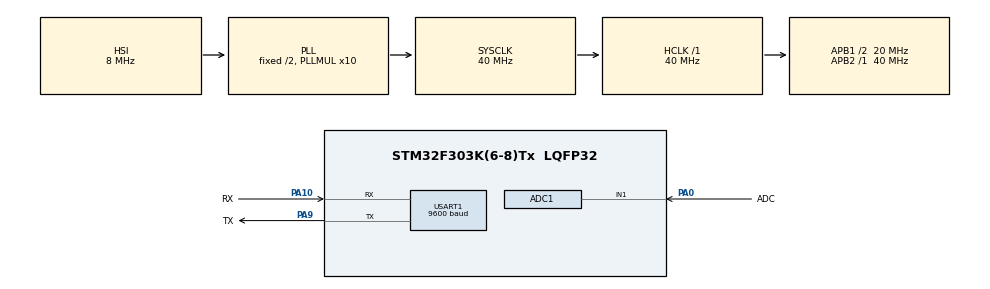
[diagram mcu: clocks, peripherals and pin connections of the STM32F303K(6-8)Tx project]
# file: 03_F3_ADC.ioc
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ADC1.Channel-0\#ChannelRegularConversion=ADC_CHANNEL_1
ADC1.ContinuousConvMode=ENABLE
ADC1.EnableInjectedConversion=DISABLE
ADC1.NbrOfConversionFlag=1
ADC1.Offset-0\#ChannelRegularConversion=0
ADC1.OffsetNumber-0\#ChannelRegularConversion=ADC_OFFSET_NONE
ADC1.Rank-0\#ChannelRegularConversion=1
ADC1.SamplingTime-0\#ChannelRegularConversion=ADC_SAMPLETIME_1CYCLE_5
ADC1.SubFamily=STM32F303x8
ADC1.master=1
Mcu.Family=STM32F3
Mcu.Name=STM32F303K(6-8)Tx
Mcu.Package=LQFP32
NVIC.PriorityGroup=NVIC_PRIORITYGROUP_4
PA0.GPIO_Label=ADC
PA0.Mode=IN1-Single-Ended
PA0.Signal=ADC1_IN1
PA10.GPIO_Label=RX
PA10.Mode=Asynchronous
PA10.Signal=USART1_RX
PA13.GPIO_Label=SWDIO
PA13.Signal=SYS_JTMS-SWDIO
PA14.GPIO_Label=SWCLK
PA14.Signal=SYS_JTCK-SWCLK
PA15.GPIO_Label=VCP_RX
PA15.Signal=USART2_RX
PA2.GPIO_Label=VCP_TX
PA2.Signal=USART2_TX
PA9.GPIO_Label=TX
PA9.Mode=Asynchronous
PA9.Signal=USART1_TX
PF0\ /\ OSC_IN.GPIO_Label=MCO
PF0\ /\ OSC_IN.Signal=RCC_OSC_IN
ProjectManager.HeapSize=0x200
ProjectManager.StackSize=0x400
ProjectManager.TargetToolchain=SW4STM32
RCC.AHBFreq_Value=40000000
RCC.APB1CLKDivider=RCC_HCLK_DIV2
RCC.APB1Freq_Value=20000000
RCC.APB1TimFreq_Value=40000000
RCC.APB2Freq_Value=40000000
RCC.APB2TimFreq_Value=40000000
RCC.CortexFreq_Value=40000000
RCC.HCLKFreq_Value=40000000
RCC.HSE_VALUE=8000000
RCC.HSI_VALUE=8000000
RCC.PLLMUL=RCC_PLL_MUL10
RCC.SYSCLKFreq_VALUE=40000000
RCC.SYSCLKSourceVirtual=RCC_SYSCLKSOURCE_PLLCLK
USART1.BaudRate=9600
USART1.Mode=UART_MODE_TX
board=NUCLEO-F303K8

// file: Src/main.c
/**
  ******************************************************************************
  * File Name          : main.c
  * Description        : Main program body
  ******************************************************************************
  *
  * COPYRIGHT(c) 2016 STMicroelectronics
  *
  * Redistribution and use in source and binary forms, with or without modification,
  * are permitted provided that the following conditions are met:
  *   1. Redistributions of source code must retain the above copyright notice,
  *      this list of conditions and the following disclaimer.
  *   2. Redistributions in binary form must reproduce the above copyright notice,
  *      this list of conditions and the following disclaimer in the documentation
  *      and/or other materials provided with the distribution.
  *   3. Neither the name of STMicroelectronics nor the names of its contributors
  *      may be used to endorse or promote products derived from this software
  *      without specific prior written permission.
  *
  * THIS SOFTWARE IS PROVIDED BY THE COPYRIGHT HOLDERS AND CONTRIBUTORS "AS IS"
  * AND ANY EXPRESS OR IMPLIED WARRANTIES, INCLUDING, BUT NOT LIMITED TO, THE
  * IMPLIED WARRANTIES OF MERCHANTABILITY AND FITNESS FOR A PARTICULAR PURPOSE ARE
  * DISCLAIMED. IN NO EVENT SHALL THE COPYRIGHT HOLDER OR CONTRIBUTORS BE LIABLE
  * FOR ANY DIRECT, INDIRECT, INCIDENTAL, SPECIAL, EXEMPLARY, OR CONSEQUENTIAL
  * DAMAGES (INCLUDING, BUT NOT LIMITED TO, PROCUREMENT OF SUBSTITUTE GOODS OR
  * SERVICES; LOSS OF USE, DATA, OR PROFITS; OR BUSINESS INTERRUPTION) HOWEVER
  * CAUSED AND ON ANY THEORY OF LIABILITY, WHETHER IN CONTRACT, STRICT LIABILITY,
  * OR TORT (INCLUDING NEGLIGENCE OR OTHERWISE) ARISING IN ANY WAY OUT OF THE USE
  * OF THIS SOFTWARE, EVEN IF ADVISED OF THE POSSIBILITY OF SUCH DAMAGE.
  *
  ******************************************************************************
  */
#include "stm32f3xx_hal.h"

ADC_HandleTypeDef hadc1;

UART_HandleTypeDef huart1;

/* USER CODE BEGIN PV */
/* Private variables ---------------------------------------------------------*/
	uint16_t ADCResult=0;
	char buf[20];
/* USER CODE END PV */

void SystemClock_Config(void);
void Error_Handler(void);
static void MX_GPIO_Init(void);
static void MX_ADC1_Init(void);
static void MX_USART1_UART_Init(void);

/* USER CODE BEGIN PFP */
/* Private function prototypes -----------------------------------------------*/

/* USER CODE END PFP */

int main(void)
{

  /* MCU Configuration----------------------------------------------------------*/

  /* Reset of all peripherals, Initializes the Flash interface and the Systick. */
  HAL_Init();

  /* Configure the system clock */
  SystemClock_Config();

  /* Initialize all configured peripherals */
  MX_GPIO_Init();
  MX_ADC1_Init();
  MX_USART1_UART_Init();

  /* Infinite loop */
  while (1)
  {

  /* USER CODE BEGIN 3 */
	  ADCResult = HAL_ADC_GetValue(&hadc1);
	  sprintf(buf, "ADC Value: %d\n", ADCResult);
	  HAL_UART_Transmit(&huart1, buf, 20, 10);
	  HAL_Delay(1000);
  }
  /* USER CODE END 3 */

}

/** System Clock Configuration
*/
void SystemClock_Config(void)
{

  RCC_OscInitTypeDef RCC_OscInitStruct;
  RCC_ClkInitTypeDef RCC_ClkInitStruct;
  RCC_PeriphCLKInitTypeDef PeriphClkInit;

  RCC_OscInitStruct.OscillatorType = RCC_OSCILLATORTYPE_HSI;
  RCC_OscInitStruct.HSIState = RCC_HSI_ON;
  RCC_OscInitStruct.HSICalibrationValue = 16;
  RCC_OscInitStruct.PLL.PLLState = RCC_PLL_ON;
  RCC_OscInitStruct.PLL.PLLSource = RCC_PLLSOURCE_HSI;
  RCC_OscInitStruct.PLL.PLLMUL = RCC_PLL_MUL10;
  if (HAL_RCC_OscConfig(&RCC_OscInitStruct) != HAL_OK)
  {
    Error_Handler();
  }

  RCC_ClkInitStruct.ClockType = RCC_CLOCKTYPE_HCLK|RCC_CLOCKTYPE_SYSCLK
                              |RCC_CLOCKTYPE_PCLK1|RCC_CLOCKTYPE_PCLK2;
  RCC_ClkInitStruct.SYSCLKSource = RCC_SYSCLKSOURCE_PLLCLK;
  RCC_ClkInitStruct.AHBCLKDivider = RCC_SYSCLK_DIV1;
  RCC_ClkInitStruct.APB1CLKDivider = RCC_HCLK_DIV2;
  RCC_ClkInitStruct.APB2CLKDivider = RCC_HCLK_DIV1;
  if (HAL_RCC_ClockConfig(&RCC_ClkInitStruct, FLASH_LATENCY_1) != HAL_OK)
  {
    Error_Handler();
  }

  PeriphClkInit.PeriphClockSelection = RCC_PERIPHCLK_USART1|RCC_PERIPHCLK_ADC12;
  PeriphClkInit.Usart1ClockSelection = RCC_USART1CLKSOURCE_PCLK1;
  PeriphClkInit.Adc12ClockSelection = RCC_ADC12PLLCLK_DIV1;
  if (HAL_RCCEx_PeriphCLKConfig(&PeriphClkInit) != HAL_OK)
  {
    Error_Handler();
  }

  HAL_SYSTICK_Config(HAL_RCC_GetHCLKFreq()/1000);

  HAL_SYSTICK_CLKSourceConfig(SYSTICK_CLKSOURCE_HCLK);

  /* SysTick_IRQn interrupt configuration */
  HAL_NVIC_SetPriority(SysTick_IRQn, 0, 0);
}

/* ADC1 init function */
static void MX_ADC1_Init(void)
{

  ADC_ChannelConfTypeDef sConfig;

    /**Common config
    */
  hadc1.Instance = ADC1;
  hadc1.Init.ClockPrescaler = ADC_CLOCK_ASYNC_DIV1;
  hadc1.Init.Resolution = ADC_RESOLUTION_12B;
  hadc1.Init.ScanConvMode = ADC_SCAN_DISABLE;
  hadc1.Init.ContinuousConvMode = ENABLE;
  hadc1.Init.DiscontinuousConvMode = DISABLE;
  hadc1.Init.ExternalTrigConvEdge = ADC_EXTERNALTRIGCONVEDGE_NONE;
  hadc1.Init.DataAlign = ADC_DATAALIGN_RIGHT;
  hadc1.Init.NbrOfConversion = 1;
  hadc1.Init.DMAContinuousRequests = DISABLE;
  hadc1.Init.EOCSelection = ADC_EOC_SINGLE_CONV;
  hadc1.Init.LowPowerAutoWait = DISABLE;
  hadc1.Init.Overrun = ADC_OVR_DATA_OVERWRITTEN;
  if (HAL_ADC_Init(&hadc1) != HAL_OK)
  {
    Error_Handler();
  }

    /**Configure Regular Channel
    */
  sConfig.Channel = ADC_CHANNEL_1;
  sConfig.Rank = 1;
  sConfig.SingleDiff = ADC_SINGLE_ENDED;
  sConfig.SamplingTime = ADC_SAMPLETIME_1CYCLE_5;
  sConfig.OffsetNumber = ADC_OFFSET_NONE;
  sConfig.Offset = 0;
  if (HAL_ADC_ConfigChannel(&hadc1, &sConfig) != HAL_OK)
  {
    Error_Handler();
  }

  HAL_ADC_Start(&hadc1);

}

/* USART1 init function */
static void MX_USART1_UART_Init(void)
{

  huart1.Instance = USART1;
  huart1.Init.BaudRate = 9600;
  huart1.Init.WordLength = UART_WORDLENGTH_8B;
  huart1.Init.StopBits = UART_STOPBITS_1;
  huart1.Init.Parity = UART_PARITY_NONE;
  huart1.Init.Mode = UART_MODE_TX;
  huart1.Init.HwFlowCtl = UART_HWCONTROL_NONE;
  huart1.Init.OverSampling = UART_OVERSAMPLING_16;
  huart1.Init.OneBitSampling = UART_ONE_BIT_SAMPLE_DISABLE;
  huart1.AdvancedInit.AdvFeatureInit = UART_ADVFEATURE_NO_INIT;
  if (HAL_UART_Init(&huart1) != HAL_OK)
  {
    Error_Handler();
  }

}

/** Configure pins as
        * Analog
        * Input
        * Output
        * EVENT_OUT
        * EXTI
     PA2   ------> USART2_TX
     PA15   ------> USART2_RX
*/
static void MX_GPIO_Init(void)
{

  GPIO_InitTypeDef GPIO_InitStruct;

  /* GPIO Ports Clock Enable */
  __HAL_RCC_GPIOF_CLK_ENABLE();
  __HAL_RCC_GPIOA_CLK_ENABLE();

  /*Configure GPIO pins : VCP_TX_Pin VCP_RX_Pin */
  GPIO_InitStruct.Pin = VCP_TX_Pin|VCP_RX_Pin;
  GPIO_InitStruct.Mode = GPIO_MODE_AF_PP;
  GPIO_InitStruct.Pull = GPIO_NOPULL;
  GPIO_InitStruct.Speed = GPIO_SPEED_FREQ_HIGH;
  GPIO_InitStruct.Alternate = GPIO_AF7_USART2;
  HAL_GPIO_Init(GPIOA, &GPIO_InitStruct);

}

void Error_Handler(void)
{
  while(1)
  {
  }
}

/************************ (C) COPYRIGHT STMicroelectronics *****END OF FILE****/
